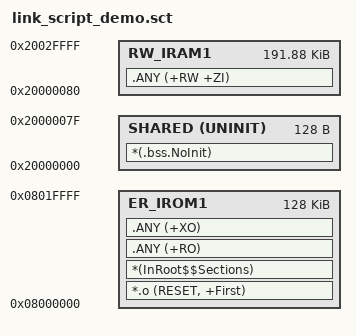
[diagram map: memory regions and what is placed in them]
; ******************************************************************
; *** Scatter-Loading Description File generated by Embedded IDE ***
; ******************************************************************

LR_IROM1 0x08000000 0x00020000 {
	ER_IROM1 0x08000000 0x00020000 {
		*.o (RESET, +First) 
		*(InRoot$$Sections) 
		.ANY (+RO) 
		.ANY (+XO) 
	}
	SHARED 0x20000000 UNINIT 0x80  {
		*(.bss.NoInit)
	}
	RW_IRAM1 0x20000000+0x80 0x00030000-0x80 {
		.ANY (+RW +ZI) 
	}
}

